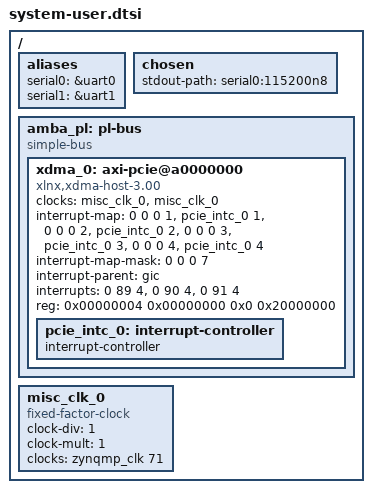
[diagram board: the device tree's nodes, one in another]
/*
 * FPGA Drive FMC reference design DT overlay for ZCU106 (EDF flow).
 *
 * This overlay is the zcu106_hpc1 variant: 1x xilinx_xdma 1-lane Root Port
 * for the single M.2 socket reachable from the ZCU106 HPC1 FMC connector
 * (HPC1 only routes one GT quad usefully to the FPGA Drive FMC). The
 * bbappend selects the per-target file via FPGADRV_TARGET (see
 * device-tree.bbappend).
 *
 * The SoC-side hardware (cortexa53, uart, gem, sdhci, etc.) is described
 * by the AMD-validated cortexa53-linux.dts in meta-amd-adaptive-socs-bsp.
 * This file is appended to that DT (via EXTRA_DT_INCLUDE_FILES) to add
 * the FPGA Drive PL hardware — a single xilinx_xdma PCIe Root Complex
 * controller wired to GIC interrupts 89/90/91.
 *
 * The xdma_0 node here was generated by `xsct hsi::generate_target`
 * against Vivado/zcu106_hpc1/fpgadrv_wrapper.xsa using device-tree-xlnx
 * (xlnx_rel_v2025.2). When the Vivado BD changes, regenerate by running:
 *
 *   xsct -eval "hsi::open_hw_design <xsa>; \
 *               hsi::set_repo_path <device-tree-xlnx>; \
 *               hsi::create_sw_design device-tree -os device_tree \
 *                   -proc psu_cortexa53_0; \
 *               hsi::generate_target -dir /tmp/dtg_out"
 *
 * and copy /tmp/dtg_out/pl.dtsi's pl-bus contents over the block below.
 *
 * Aliases pin stdout to UART0 (the actual silkscreened "UART 0" on the
 * ZCU106).
 */

/ {
   aliases {
      serial0 = &uart0;
      serial1 = &uart1;
   };
   chosen {
      stdout-path = "serial0:115200n8";
   };

   amba_pl: pl-bus {
      #address-cells = <2>;
      #size-cells = <2>;
      compatible = "simple-bus";
      ranges;

      xdma_0: axi-pcie@a0000000 {
         #address-cells = <3>;
         #interrupt-cells = <1>;
         #size-cells = <2>;
         clock-names = "sys_clk", "sys_clk_gt";
         clocks = <&misc_clk_0>, <&misc_clk_0>;
         compatible = "xlnx,xdma-host-3.00";
         device_type = "pci";
         interrupt-map = <0 0 0 1 &pcie_intc_0 1>,
                         <0 0 0 2 &pcie_intc_0 2>,
                         <0 0 0 3 &pcie_intc_0 3>,
                         <0 0 0 4 &pcie_intc_0 4>;
         interrupt-map-mask = <0 0 0 7>;
         interrupt-names = "misc", "msi0", "msi1";
         interrupt-parent = <&gic>;
         interrupts = <0 89 4>, <0 90 4>, <0 91 4>;
         ranges = <0x02000000 0x00000000 0xA0000000 0x0 0xA0000000 0x00000000 0x10000000>;
         reg = <0x00000004 0x00000000 0x0 0x20000000>;
         pcie_intc_0: interrupt-controller {
            #address-cells = <0>;
            #interrupt-cells = <1>;
            interrupt-controller;
         };
      };
   };

   misc_clk_0: misc_clk_0 {
      #clock-cells = <0>;
      clock-div = <1>;
      clock-mult = <1>;
      clocks = <&zynqmp_clk 71>;
      compatible = "fixed-factor-clock";
   };
};
